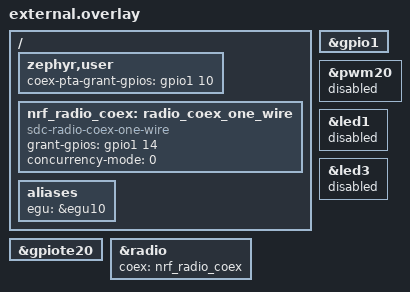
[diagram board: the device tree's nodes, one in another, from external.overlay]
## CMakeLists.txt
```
# SPDX-License-Identifier: MIT

cmake_minimum_required(VERSION 3.20.0)

find_package(Zephyr REQUIRED HINTS $ENV{ZEPHYR_BASE})
project(nucode_m32_coexistence_contract)

get_filename_component(NUCODE_ROOT "${CMAKE_CURRENT_LIST_DIR}/../../.." ABSOLUTE)
target_sources(app PRIVATE
    src/main.cpp
    "${NUCODE_ROOT}/libraries/NUCODE_Radio_Coexistence/src/NUCODE_Radio_Coexistence.cpp"
)
target_include_directories(app PRIVATE
    "${NUCODE_ROOT}/libraries/NUCODE_Radio_Coexistence/src"
)
```

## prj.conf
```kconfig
# SPDX-License-Identifier: MIT

CONFIG_CPP=y
CONFIG_STD_CPP17=y
CONFIG_CPP_EXCEPTIONS=n
CONFIG_CPP_RTTI=n
CONFIG_NUCODE_ARDUINO_CORE=y
CONFIG_NUCODE_ARDUINO_RUNTIME=n
CONFIG_NUCODE_ARDUINO_API=y
CONFIG_NUCODE_ARDUINO_GPIO=n
CONFIG_NUCODE_ARDUINO_INTERRUPTS=n
CONFIG_NUCODE_ARDUINO_TIME=n
CONFIG_NUCODE_ARDUINO_SERIAL=n
CONFIG_NUCODE_ARDUINO_WIRE=n
CONFIG_NUCODE_ARDUINO_SPI=n
CONFIG_NUCODE_ARDUINO_ADC=n
CONFIG_NUCODE_ARDUINO_PWM=n
CONFIG_NUCODE_RADIO_COEXISTENCE=y
```

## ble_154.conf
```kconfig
# SPDX-License-Identifier: MIT
CONFIG_BT=y
CONFIG_BT_PERIPHERAL=y
CONFIG_BT_MAX_CONN=1
CONFIG_BT_CTLR_SDC_PERIPHERAL_COUNT=1
CONFIG_MPSL=y
CONFIG_NRF_802154_RADIO_DRIVER=y
CONFIG_NRF_802154_DRV_REINIT_ENABLED=y
```

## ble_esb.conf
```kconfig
# SPDX-License-Identifier: MIT
CONFIG_BT=y
CONFIG_BT_PERIPHERAL=y
CONFIG_BT_MAX_CONN=1
CONFIG_BT_CTLR_SDC_PERIPHERAL_COUNT=1
CONFIG_ESB=y
CONFIG_ESB_MAX_PAYLOAD_LENGTH=32
CONFIG_CLOCK_CONTROL=y
CONFIG_ESB_CLOCK_INIT=y
CONFIG_ESB_MPSL_TIMESLOT=y
CONFIG_MPSL_TIMESLOT_SESSION_COUNT=2
```

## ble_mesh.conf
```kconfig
# SPDX-License-Identifier: MIT
CONFIG_BT=y
CONFIG_BT_PERIPHERAL=y
CONFIG_BT_CENTRAL=y
CONFIG_BT_OBSERVER=y
CONFIG_BT_BROADCASTER=y
CONFIG_BT_MAX_CONN=2
CONFIG_BT_CTLR_SDC_PERIPHERAL_COUNT=1
CONFIG_BT_EXT_ADV=y
CONFIG_BT_EXT_ADV_MAX_ADV_SET=6
CONFIG_BT_MESH=y
CONFIG_BT_MESH_PB_ADV=y
CONFIG_BT_MESH_PB_GATT=y
CONFIG_BT_MESH_PROVISIONER=y
CONFIG_BT_MESH_CDB=y
CONFIG_BT_MESH_CDB_NODE_COUNT=2
CONFIG_BT_SETTINGS=y
CONFIG_SETTINGS=y
CONFIG_SETTINGS_ZMS=y
CONFIG_FLASH=y
CONFIG_FLASH_MAP=y
CONFIG_ZMS=y
```

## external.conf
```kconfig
# SPDX-License-Identifier: MIT
CONFIG_BT=y
CONFIG_BT_PERIPHERAL=y
CONFIG_BT_MAX_CONN=1
CONFIG_BT_CTLR_SDC_PERIPHERAL_COUNT=1
CONFIG_MPSL_CX=y
CONFIG_MPSL_CX_1WIRE=y
CONFIG_NUCODE_RADIO_COEX_ONEWIRE=y
```

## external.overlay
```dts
/**
 * @file external.overlay
 * @brief M32-W10 native target의 P1.10/P1.14 1-wire 공존 연결입니다.
 * SPDX-License-Identifier: MIT
 */

/ {
    zephyr,user {
        coex-pta-grant-gpios = <&gpio1 10 GPIO_ACTIVE_HIGH>;
    };

    nrf_radio_coex: radio_coex_one_wire {
        status = "okay";
        compatible = "sdc-radio-coex-one-wire";
        grant-gpios = <&gpio1 14 GPIO_ACTIVE_HIGH>;
        concurrency-mode = <0>;
    };

    aliases {
        egu = &egu10;
    };
};

&gpio1 {
    status = "okay";
};

&gpiote20 {
    status = "okay";
};

&pwm20 {
    status = "disabled";
};

&led1 {
    status = "disabled";
};

&led3 {
    status = "disabled";
};

&radio {
    coex = <&nrf_radio_coex>;
};
```

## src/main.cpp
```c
/**
 * @file main.cpp
 * @brief M32-W10 공존 telemetry와 1-wire 공개 API target compile 계약입니다.
 *
 * SPDX-License-Identifier: MIT
 */

#include <NUCODE_Radio_Coexistence.h>

/** @brief 모든 bounded 관측 signature를 target compiler로 확인합니다. */
int main()
{
    using nucode::coexistence::Protocol;

    static_cast<void>(NUCODECoexistence.begin(500U));
    NUCODECoexistence.recordRequested(Protocol::ble);
    NUCODECoexistence.recordDelivered(Protocol::ble, 1U, 0x12345678U, true);
    NUCODECoexistence.recordDropped(Protocol::mesh);
    NUCODECoexistence.recordTimeslotFailure(Protocol::esb);
    NUCODECoexistence.recordRestart(Protocol::ieee802154);
    NUCODECoexistence.setActive(Protocol::external_radio, true);
    static_cast<void>(NUCODECoexistence.statistics(Protocol::ble));
    static_cast<void>(NUCODECoexistence.healthy());
    static_cast<void>(NUCODECoexistence.oneWireSupported());
    static_cast<void>(NUCODECoexistence.radioEventCount());

#if defined(CONFIG_NUCODE_RADIO_COEX_ONEWIRE)
    static_cast<void>(NUCODECoexistence.beginOneWire());
    static_cast<void>(NUCODECoexistence.setExternalGrant(true));
#endif
    NUCODECoexistence.stop();
    return 0;
}
```
